VERSION ""

NS_ :

BS_:

BU_: PEDAL_BOX

BO_ 1648 PEDAL_BOX_ANALOG: 3 PEDAL_BOX
 SG_ DAMPER_FL : 0|12@1+ (0.0008058608058608059,0) [0|3.3] "V" Vector__XXX
 SG_ DAMPER_FR : 12|12@1+ (0.0008058608058608059,0) [0|3.3] "V" Vector__XXX

BO_ 1653 PEDAL_BOX_DIGITAL: 1 PEDAL_BOX
 SG_ BSPD_STATUS : 0|1@1+ (1,0) [0|1] "bool" Vector__XXX
 SG_ GPS_PPS : 1|1@1+ (1,0) [0|1] "bool" Vector__XXX

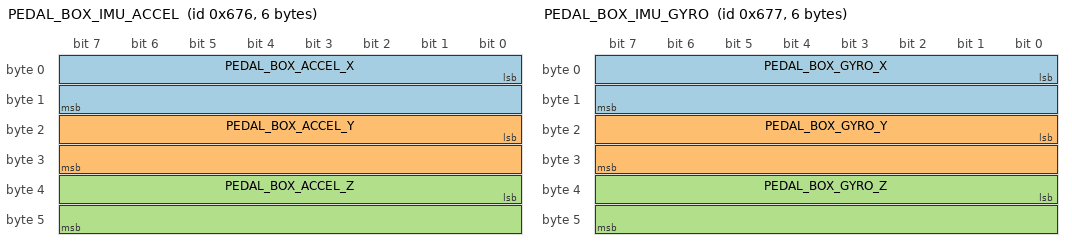
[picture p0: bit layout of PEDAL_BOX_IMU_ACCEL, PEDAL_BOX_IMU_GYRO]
BO_ 1654 PEDAL_BOX_IMU_ACCEL: 6 PEDAL_BOX
 SG_ PEDAL_BOX_ACCEL_X : 0|16@1- (0.000122,0) [-4|4] "g" Vector__XXX
 SG_ PEDAL_BOX_ACCEL_Y : 16|16@1- (0.000122,0) [-4|4] "g" Vector__XXX
 SG_ PEDAL_BOX_ACCEL_Z : 32|16@1- (0.000122,0) [-4|4] "g" Vector__XXX

BO_ 1655 PEDAL_BOX_IMU_GYRO: 6 PEDAL_BOX
 SG_ PEDAL_BOX_GYRO_X : 0|16@1- (0.0175,0) [-500|500] "dps" Vector__XXX
 SG_ PEDAL_BOX_GYRO_Y : 16|16@1- (0.0175,0) [-500|500] "dps" Vector__XXX
 SG_ PEDAL_BOX_GYRO_Z : 32|16@1- (0.0175,0) [-500|500] "dps" Vector__XXX

BO_ 1656 PEDAL_BOX_TEMP: 4 PEDAL_BOX
 SG_ PEDAL_BOX_IMU_TEMP : 0|16@1- (0.00390625,25) [-40|85] "degC" Vector__XXX
 SG_ PEDAL_BOX_AMBIENT_TEMP : 16|16@1- (0.0625,0) [-55|125] "degC" Vector__XXX

BO_ 1657 PEDAL_BOX_STATUS: 1 PEDAL_BOX
 SG_ PEDAL_BOX_ISM330_OK : 0|1@1+ (1,0) [0|1] "" Vector__XXX
 SG_ PEDAL_BOX_MCP9800_OK : 1|1@1+ (1,0) [0|1] "" Vector__XXX
